# MB9BFD1xS register map
File version: 1.7
Registers are 32-bit, read-write, reset 0x0 unless marked. A register's access mark holds for its fields unless they carry their own. Offsets are from the block's base; [hi:lo] are bit positions; {n}, {i} and the like mark numbered series; 'fields as' and 'values as' point back to an identical list.

## USBETHERCLK — USB/Ethernet Clock
Base 0x40036000
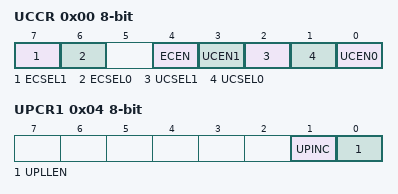
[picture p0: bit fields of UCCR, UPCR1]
0x00 UCCR 8-bit (reset mask 0x7F) — USB/Ethernet-PLL Clock Control Register
  [7] ECSEL1 — Ethernet clock selection bit 1
  [6] ECSEL0 — Ethernet clock selection bit 0
  [4] ECEN — Ethernet clock output enable bit
  [3] UCEN1 — USB1 clock output enable bit
  [2] UCSEL1 — USB1 clock selection bit
  [1] UCSEL0 — USB0 clock selection bit
  [0] UCEN0 — USB0 clock output enable bit
0x04 UPCR1 8-bit — USB/Ethernet-PLL Control Register 1
  [1] UPINC — USB/Ethernet-PLL input clock selection bit
  [0] UPLLEN — USB/Ethernet-PLL oscillation enable bit
0x08 UPCR2 8-bit — USB/Ethernet-PLL Control Register 2
  [2:0] UPOWT — USB/Ethernet-PLL oscillation stabilization wait time setting bit
0x0C UPCR3 8-bit — USB/Ethernet-PLL Control Register 3
  [4:0] UPLLK — Frequency division ratio (K) setting bit of the USB/Ethernet-PLL clock
0x10 UPCR4 8-bit reset 0x3B — USB/Ethernet-PLL Control Register 4
  [6:0] UPLLN — Frequency division ratio (N) setting bit of the USB/Ethernet-PLL clock
0x14 UP_STR 8-bit ro — USB/Ethernet-PLL Status Register
  [0] UPRDY — USB/Ethernet-PLL oscillation stabilization bit
0x18 UPINT_ENR 8-bit — USB/Ethernet-PLL Interrupt Source Enable Register
  [0] UPCSE — USB/Ethernet-PLL oscillation stabilization wait complete interrupt enable bit
0x1C UPINT_CLR 8-bit wo — USB/Ethernet-PLL Interrupt Source Clear Register
  [0] UPCSC — USB/Ethernet-PLL oscillation stabilization interrupt source clear bit
0x20 UPINT_STR 8-bit ro — USB/Ethernet-PLL Interrupt Source Status Register
  [0] UPCSI — USB/Ethernet-PLL interrupt source status bit
0x24 UPCR5 8-bit reset 0x4 — USB/Ethernet-PLL Control Register 5
  [3:0] UPLLM — Frequency division ratio (M) setting bit of the USB/Ethernet-PLL clock
0x28 UPCR6 8-bit reset 0x2 — USB/Ethernet-PLL Setting Register 6
  [3:0] UBSR — CLKPLL division ratio setting bit
0x2C UPCR7 8-bit — USB/Ethernet-PLL Setting Register 7
  [0] EPLLEN — USB/Ethernet-PLL control bit in Timer mode
0x30 USBEN0 8-bit — USB0 Enable Register
  [0] USBEN0 — USB0 enable bit
0x34 USBEN1 8-bit — USB1 Enable Register
  [0] USBEN1 — USB1 enable bit

## DMAC — DMAC Registers
Base 0x40060000
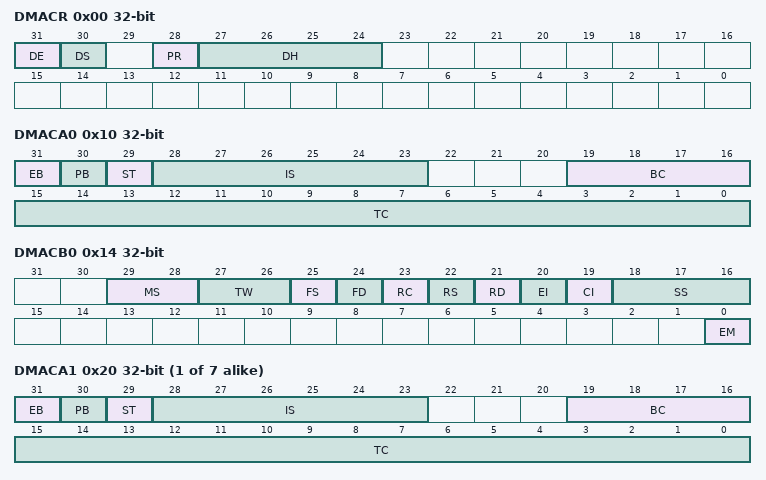
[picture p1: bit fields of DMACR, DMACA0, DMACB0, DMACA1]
0x00 DMACR — Entire DMAC Configuration Register
  [31] DE — DMA Enable (all-channel operation enable bit)
  [30] DS — DMA Stop
  [28] PR — Priority Rotation
  [27:24] DH — DMA Halt (All-channel pause bit)
0x10 DMACA0 — Configuration A Register
  [31] EB — Enable bit (individual-channel operation enable bit)
  [30] PB — Pause bit (individual-channel pause bit)
  [29] ST — Software Trigger
  [28:23] IS — Input Select
  [19:16] BC — Block Count
  [15:0] TC — Transfer Count
0x14 DMACB0 — Configuration B Register
  [29:28] MS — Mode Select
  [27:26] TW — Transfer Width
  [25] FS — Fixed Source
  [24] FD — Fixed Destination
  [23] RC — Reload Count (BC/TC reload)
  [22] RS — Reload Source
  [21] RD — Reload Destination
  [20] EI — Error Interrupt (unsuccessful transfer completion interrupt enable)
  [19] CI — Completion Interrupt (successful transfer completion interrupt enable)
  [18:16] SS — Stop Status (stop status notification)
  [0] EM — Enable bit Mask (EB bit clear mask)
0x18 DMACSA0 — Transfer Source Address Register
0x1C DMACDA0 — Transfer Destination Address Register
{0x10+0x10*i} DMACA{i} (i=1..7) — Configuration A Register {i}
  fields as DMACA0
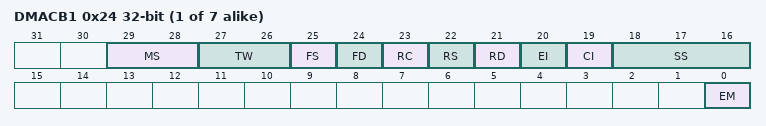
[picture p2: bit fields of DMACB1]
{0x14+0x10*i} DMACB{i} (i=1..7) — Configuration B Register {i}
  fields as DMACB0
{0x18+0x10*i} DMACSA{i} (i=1..7) — Transfer Source Address Register {i}
{0x1C+0x10*i} DMACDA{i} (i=1..7) — Transfer Destination Address Register {i}

## CANPRES — CAN Prescaler Register
Base 0x40037000
0x00 CANPRE 8-bit reset 0xB (reset mask 0xF) — CAN Prescaler Register

## ETHERNET_CONTROL — Ethernet system control
Base 0x40066000
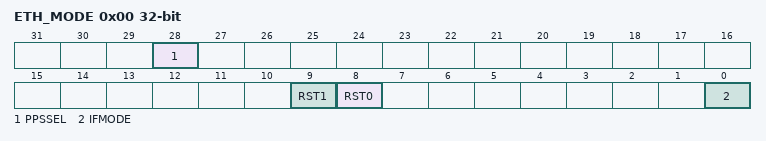
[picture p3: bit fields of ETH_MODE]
0x00 ETH_MODE — Mode Select Register
  [28] PPSSEL — Select either of the system time counter pulse outputs of the Ethernet-MAC PTP function to output to E_PPS0_PPS1 pin
  [9] RST1 — reset signal against Ethernet-MAC (ch.1)
  [8] RST0 — reset signal against Ethernet-MAC (ch.0)
  [0] IFMODE — Mode selector
0x08 ETH_CLKG — Clock Gating Register
  [1:0] MACEN — Select the system clock supply to Ethernet-MAC

## Notices in the file
Licence Terms
FUJITSU SEMICONDUCTOR LIMITED (gLICENSORh) hereby grants and
you (gLICENSEEh) hereby accept a non transferable, non-exclusive
licence to use and copy the deliverables (gDeliverablesh) solely for
the purpose of; (i) developing LICENSEEfs development tools and
distributing such development tools to third parties; (ii) generating
derivative representations of the Deliverables to develop and debug
software for LICENSORfs targeted devices or device series identified
within the Deliverables, (together the gPurposeh) under the following
terms and conditions:
1. Ownership.
The Deliverables are the property of LICENSOR. LICENSEE acquires no
right, title or interest in the Deliverables other than the licence
rights granted herein.
2. Use.
LICENSEE shall only be permitted to use the Deliverables for the
Purpose. LICENSEE shall not reverse engineer, decompile or
disassemble the Deliverables, in whole or in part.
3. Copies.
All copies of the Deliverables must bear the same notice(s) contained
on the original copies of the Deliverables.
4. No Warranty.
THE DELIVERABLES ARE PROVIDED gAS ISh AND ANY EXPRESS, IMPLIED OR
STATUTORY WARRANTIES, INCLUDING, BUT NOT LIMITED TO, THE IMPLIED
WARRANTIES OF MERCHANTABILITY, SATISFACTORY QUALITY AND FITNESS FOR
A PARTICULAR PURPOSE ARE DISCLAIMED.
IN NO EVENT SHALL LICENSOR BE LIABLE FOR ANY DIRECT, INDIRECT,
INCIDENTAL, SPECIAL, EXEMPLARY, OR CONSEQUENTIAL DAMAGES HOWEVER CAUSED
AND ON ANY THEORY OF LIABILITY, WHETHER IN CONTRACT, STRICT LIABILITY,
OR TORT (INCLUDING NEGLIGENCE OR OTHERWISE) ARISING IN ANY WAY OUT OF
THE USE OF THE DELIVERABLES, EVEN IF ADVISED OF THE POSSIBILITY OF SUCH
DAMAGE.
LICENSEE EXPRESSLY ASSUMES ALL LIABILITIES AND RISKS, FOR USE OR
OPERATION OF THE DELIVERABLES.
5.In the event that LICENSEE receives early access to the Deliverables,
LICENSEE acknowledges and agrees that;
(a) notwithstanding the licence grants above, LICENSEE shall only be
permitted to use the Deliverables solely internally for evaluation and
providing feedback to LICENSOR;
(b) except with respect to the limited licence grants in 5(a), LICENSEE
shall be subject to all of the terms and conditions set out above; and
(c) the Deliverables are confidential information and LICENSEE shall
maintain in confidence the Deliverables and apply security measures no
less stringent than the measures that LICENSEE applies to its own like
information, but not less than a reasonable degree of care, to prevent
unauthorised disclosure and use of the Deliverables.
